# STM32F410 register map
File version: 1.3
CPU: CM4 r0p1, little endian, MPU, FPU, 4 interrupt priority bits
Registers are 32-bit, read-write, reset 0x0 unless marked. A register's access mark holds for its fields unless they carry their own. Offsets are from the block's base; [hi:lo] are bit positions; {n}, {i} and the like mark numbered series.

## RCC — Reset and clock control
Base 0x40023800
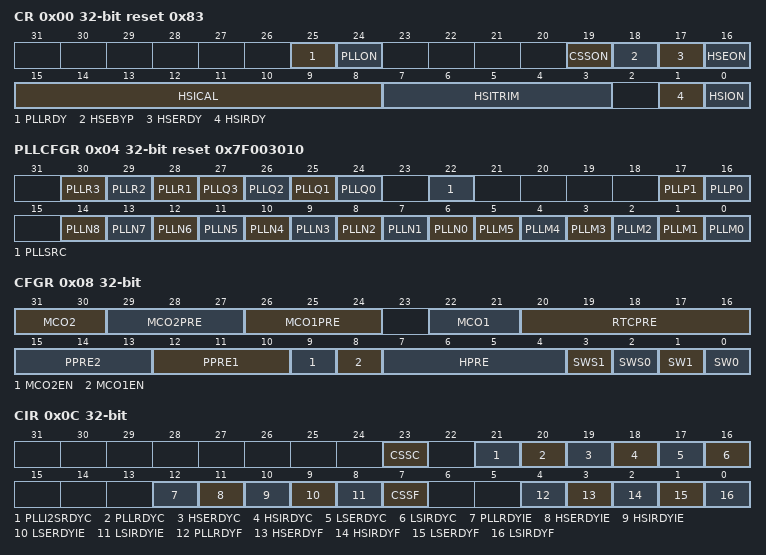
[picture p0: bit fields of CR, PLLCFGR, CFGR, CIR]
0x00 CR access per field reset 0x83 — clock control register
  [25] PLLRDY ro — Main PLL (PLL) clock ready flag
  [24] PLLON rw — Main PLL (PLL) enable
  [19] CSSON rw — Clock security system enable
  [18] HSEBYP rw — HSE clock bypass
  [17] HSERDY ro — HSE clock ready flag
  [16] HSEON rw — HSE clock enable
  [15:8] HSICAL ro — Internal high-speed clock calibration
  [7:3] HSITRIM rw — Internal high-speed clock trimming
  [1] HSIRDY ro — Internal high-speed clock ready flag
  [0] HSION rw — Internal high-speed clock enable
0x04 PLLCFGR reset 0x7F003010 — PLL configuration register
  [30] PLLR3
  [29] PLLR2
  [28] PLLR1
  [n+24] PLLQ{n} (n=0..3) — Main PLL (PLL) division factor for USB OTG FS, SDIO and random number generator clocks
  [22] PLLSRC — Main PLL(PLL) and audio PLL (PLLI2S) entry clock source
  [17] PLLP1 — Main PLL (PLL) division factor for main system clock
  [16] PLLP0 — Main PLL (PLL) division factor for main system clock
  [n+6] PLLN{n} (n=0..8) — Main PLL (PLL) multiplication factor for VCO
  [n] PLLM{n} (n=0..5) — Division factor for the main PLL (PLL) and audio PLL (PLLI2S) input clock
0x08 CFGR access per field — clock configuration register
  [31:30] MCO2 rw — Microcontroller clock output 2
  [29:27] MCO2PRE rw — MCO2 prescaler
  [26:24] MCO1PRE rw — MCO1 prescaler
  [22:21] MCO1 rw — Microcontroller clock output 1
  [20:16] RTCPRE rw — HSE division factor for RTC clock
  [15:13] PPRE2 rw — APB high-speed prescaler (APB2)
  [12:10] PPRE1 rw — APB Low speed prescaler (APB1)
  [9] MCO2EN rw — MCO output enable
  [8] MCO1EN rw — MCO output enable
  [7:4] HPRE rw — AHB prescaler
  [3] SWS1 ro — System clock switch status
  [2] SWS0 ro — System clock switch status
  [1] SW1 rw — System clock switch
  [0] SW0 rw — System clock switch
0x0C CIR access per field — clock interrupt register
  [23] CSSC wo — Clock security system interrupt clear
  [21] PLLI2SRDYC wo — PLLI2S ready interrupt clear
  [20] PLLRDYC wo — Main PLL(PLL) ready interrupt clear
  [19] HSERDYC wo — HSE ready interrupt clear
  [18] HSIRDYC wo — HSI ready interrupt clear
  [17] LSERDYC wo — LSE ready interrupt clear
  [16] LSIRDYC wo — LSI ready interrupt clear
  [12] PLLRDYIE rw — Main PLL (PLL) ready interrupt enable
  [11] HSERDYIE rw — HSE ready interrupt enable
  [10] HSIRDYIE rw — HSI ready interrupt enable
  [9] LSERDYIE rw — LSE ready interrupt enable
  [8] LSIRDYIE rw — LSI ready interrupt enable
  [7] CSSF ro — Clock security system interrupt flag
  [4] PLLRDYF ro — Main PLL (PLL) ready interrupt flag
  [3] HSERDYF ro — HSE ready interrupt flag
  [2] HSIRDYF ro — HSI ready interrupt flag
  [1] LSERDYF ro — LSE ready interrupt flag
  [0] LSIRDYF ro — LSI ready interrupt flag
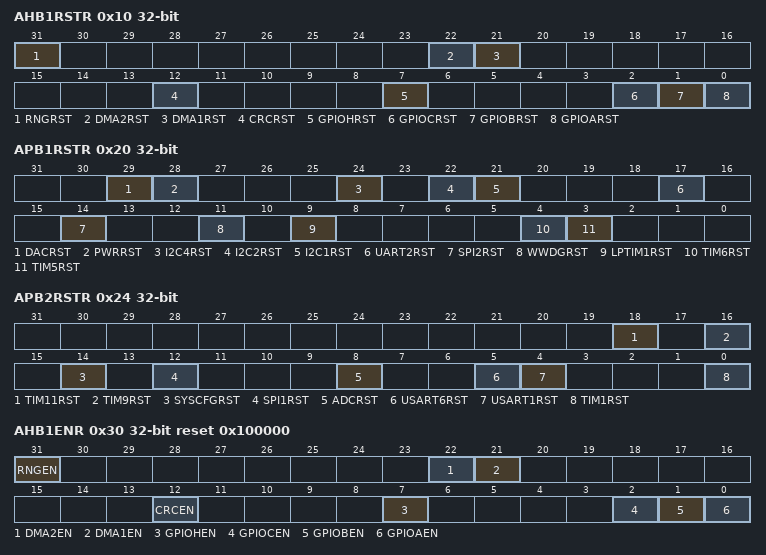
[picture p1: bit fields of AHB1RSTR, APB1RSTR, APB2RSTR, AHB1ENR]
0x10 AHB1RSTR — AHB1 peripheral reset register
  [31] RNGRST
  [22] DMA2RST — DMA2 reset
  [21] DMA1RST — DMA2 reset
  [12] CRCRST — CRC reset
  [7] GPIOHRST — IO port H reset
  [2] GPIOCRST — IO port C reset
  [1] GPIOBRST — IO port B reset
  [0] GPIOARST — IO port A reset
0x20 APB1RSTR — APB1 peripheral reset register
  [29] DACRST — DAC reset
  [28] PWRRST — Power interface reset
  [24] I2C4RST — I2C4 reset
  [22] I2C2RST — I2C 2 reset
  [21] I2C1RST — I2C 1 reset
  [17] UART2RST — USART 2 reset
  [14] SPI2RST — SPI 2 reset
  [11] WWDGRST — Window watchdog reset
  [9] LPTIM1RST — LPTIM1 reset
  [4] TIM6RST — TIM6 reset
  [3] TIM5RST — TIM5 reset
0x24 APB2RSTR — APB2 peripheral reset register
  [18] TIM11RST — TIM11 reset
  [16] TIM9RST — TIM9 reset
  [14] SYSCFGRST — System configuration controller reset
  [12] SPI1RST — SPI 1 reset
  [8] ADCRST — ADC interface reset (common to all ADCs)
  [5] USART6RST — USART6 reset
  [4] USART1RST — USART1 reset
  [0] TIM1RST — TIM1 reset
0x30 AHB1ENR reset 0x100000 — AHB1 peripheral clock register
  [31] RNGEN — RNG clock enable
  [22] DMA2EN — DMA2 clock enable
  [21] DMA1EN — DMA1 clock enable
  [12] CRCEN — CRC clock enable
  [7] GPIOHEN — IO port H clock enable
  [2] GPIOCEN — IO port C clock enable
  [1] GPIOBEN — IO port B clock enable
  [0] GPIOAEN — IO port A clock enable
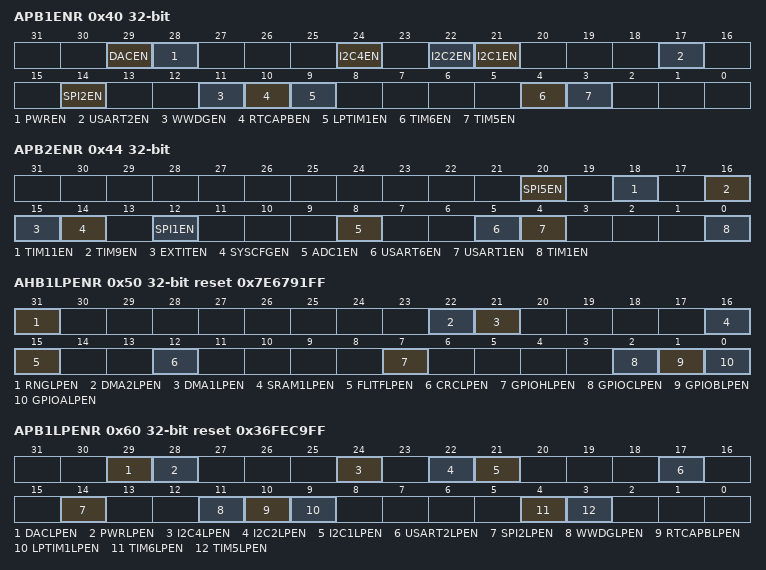
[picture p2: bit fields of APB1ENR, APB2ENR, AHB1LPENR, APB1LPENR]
0x40 APB1ENR — APB1 peripheral clock enable register
  [29] DACEN — DAC interface clock enable
  [28] PWREN — Power interface clock enable
  [24] I2C4EN — I2C4 clock enable
  [22] I2C2EN — I2C2 clock enable
  [21] I2C1EN — I2C1 clock enable
  [17] USART2EN — USART 2 clock enable
  [14] SPI2EN — SPI2 clock enable
  [11] WWDGEN — Window watchdog clock enable
  [10] RTCAPBEN — RTC APB clock enable
  [9] LPTIM1EN — LPTIM1 clock enable
  [4] TIM6EN — TIM6 clock enable
  [3] TIM5EN — TIM5 clock enable
0x44 APB2ENR — APB2 peripheral clock enable register
  [20] SPI5EN — SPI5 clock enable
  [18] TIM11EN — TIM11 clock enable
  [16] TIM9EN — TIM9 clock enable
  [15] EXTITEN — EXTI ans external IT clock enable
  [14] SYSCFGEN — System configuration controller clock enable
  [12] SPI1EN — SPI1 clock enable
  [8] ADC1EN — ADC1 clock enable
  [5] USART6EN — USART6 clock enable
  [4] USART1EN — USART1 clock enable
  [0] TIM1EN — TIM1 clock enable
0x50 AHB1LPENR reset 0x7E6791FF — AHB1 peripheral clock enable in low power mode register
  [31] RNGLPEN — RNG clock enable during sleep mode
  [22] DMA2LPEN — DMA2 clock enable during Sleep mode
  [21] DMA1LPEN — DMA1 clock enable during Sleep mode
  [16] SRAM1LPEN — SRAM 1interface clock enable during Sleep mode
  [15] FLITFLPEN — Flash interface clock enable during Sleep mode
  [12] CRCLPEN — CRC clock enable during Sleep mode
  [7] GPIOHLPEN — IO port H clock enable during Sleep mode
  [2] GPIOCLPEN — IO port C clock enable during Sleep mode
  [1] GPIOBLPEN — IO port B clock enable during Sleep mode
  [0] GPIOALPEN — IO port A clock enable during sleep mode
0x60 APB1LPENR reset 0x36FEC9FF — APB1 peripheral clock enable in low power mode register
  [29] DACLPEN — DAC interface clock enable during sleep mode
  [28] PWRLPEN — Power interface clock enable during Sleep mode
  [24] I2C4LPEN — I2C4 clock enable during Sleep mode
  [22] I2C2LPEN — I2C2 clock enable during Sleep mode
  [21] I2C1LPEN — I2C1 clock enable during Sleep mode
  [17] USART2LPEN — USART2 clock enable during Sleep mode
  [14] SPI2LPEN — SPI2 clock enable during Sleep mode
  [11] WWDGLPEN — Window watchdog clock enable during Sleep mode
  [10] RTCAPBLPEN — RTC APB clock enable during sleep mode
  [9] LPTIM1LPEN — LPTIM1 clock enable during sleep mode
  [4] TIM6LPEN — TIM6 clock enable during Sleep mode
  [3] TIM5LPEN — TIM5 clock enable during Sleep mode
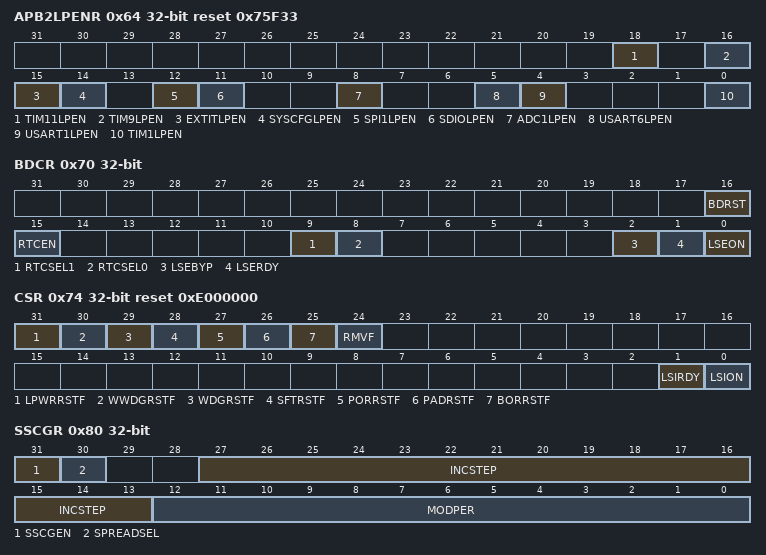
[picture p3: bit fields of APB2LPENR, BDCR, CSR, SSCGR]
0x64 APB2LPENR reset 0x75F33 — APB2 peripheral clock enabled in low power mode register
  [18] TIM11LPEN — TIM11 clock enable during Sleep mode
  [16] TIM9LPEN — TIM9 clock enable during sleep mode
  [15] EXTITLPEN — EXTI and External IT clock enable during sleep mode
  [14] SYSCFGLPEN — System configuration controller clock enable during Sleep mode
  [12] SPI1LPEN — SPI 1 clock enable during Sleep mode
  [11] SDIOLPEN — SDIO clock enable during Sleep mode
  [8] ADC1LPEN — ADC1 clock enable during Sleep mode
  [5] USART6LPEN — USART6 clock enable during Sleep mode
  [4] USART1LPEN — USART1 clock enable during Sleep mode
  [0] TIM1LPEN — TIM1 clock enable during Sleep mode
0x70 BDCR access per field — Backup domain control register
  [16] BDRST rw — Backup domain software reset
  [15] RTCEN rw — RTC clock enable
  [9] RTCSEL1 rw — RTC clock source selection
  [8] RTCSEL0 rw — RTC clock source selection
  [2] LSEBYP rw — External low-speed oscillator bypass
  [1] LSERDY ro — External low-speed oscillator ready
  [0] LSEON rw — External low-speed oscillator enable
0x74 CSR access per field reset 0xE000000 — clock control & status register
  [31] LPWRRSTF rw — Low-power reset flag
  [30] WWDGRSTF rw — Window watchdog reset flag
  [29] WDGRSTF rw — Independent watchdog reset flag
  [28] SFTRSTF rw — Software reset flag
  [27] PORRSTF rw — POR/PDR reset flag
  [26] PADRSTF rw — PIN reset flag
  [25] BORRSTF rw — BOR reset flag
  [24] RMVF rw — Remove reset flag
  [1] LSIRDY ro — Internal low-speed oscillator ready
  [0] LSION rw — Internal low-speed oscillator enable
0x80 SSCGR — spread spectrum clock generation register
  [31] SSCGEN — Spread spectrum modulation enable
  [30] SPREADSEL — Spread Select
  [27:13] INCSTEP — Incrementation step
  [12:0] MODPER — Modulation period
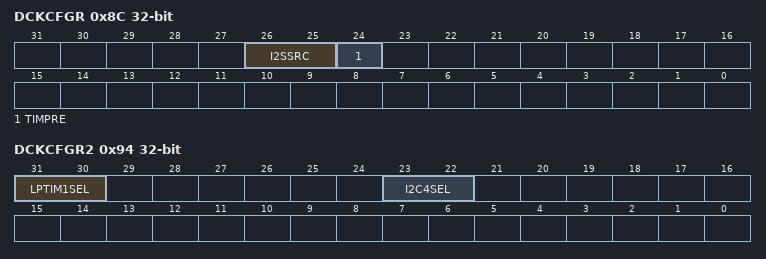
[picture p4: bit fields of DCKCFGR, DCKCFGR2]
0x8C DCKCFGR
  [26:25] I2SSRC, [24] TIMPRE
0x94 DCKCFGR2
  [31:30] LPTIM1SEL, [23:22] I2C4SEL
